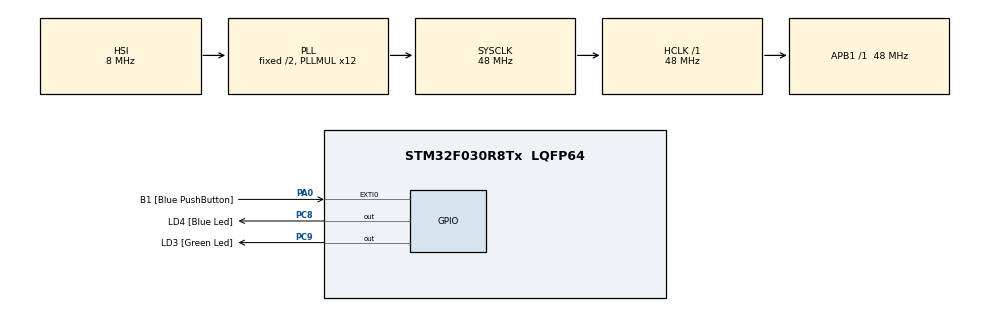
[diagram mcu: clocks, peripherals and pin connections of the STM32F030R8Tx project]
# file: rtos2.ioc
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Mcu.Family=STM32F0
FREERTOS.Tasks01=defaultTask,0,128,StartDefaultTask,Default,NULL,Dynamic,NULL,NULL
PC9.GPIO_Label=LD3 [Green Led]
PA14.GPIO_Label=SWCLK
PA0.GPIO_Label=B1 [Blue PushButton]
PC8.Signal=GPIO_Output
RCC.SYSCLKSource=RCC_SYSCLKSOURCE_PLLCLK
ProjectManager.StackSize=0x400
PC8.GPIO_Label=LD4 [Blue Led]
PA13.Signal=SYS_SWDIO
ProjectManager.TargetToolchain=STM32CubeIDE
RCC.HCLKFreq_Value=48000000
RCC.AHBFreq_Value=48000000
board=STM32F0308-DISCO
RCC.PLLMUL=RCC_PLL_MUL12
PA14.Mode=Serial_Wire
PA0.GPIO_ModeDefaultEXTI=GPIO_MODE_EVT_RISING
VP_SYS_VS_tim1.Mode=TIM1
VP_FREERTOS_VS_CMSIS_V1.Mode=CMSIS_V1
PA13.Mode=Serial_Wire
Mcu.Name=STM32F030R8Tx
PA13.GPIO_Label=SWDIO
PA0.Signal=GPXTI0
RCC.SYSCLKFreq_VALUE=48000000
Mcu.Package=LQFP64
NVIC.TimeBase=TIM1_BRK_UP_TRG_COM_IRQn
NVIC.TimeBaseIP=TIM1
PA14.Signal=SYS_SWCLK
ProjectManager.HeapSize=0x200
RCC.APB1TimFreq_Value=48000000
PC9.Signal=GPIO_Output
RCC.APB1Freq_Value=48000000
NVIC.TIM1_BRK_UP_TRG_COM_IRQn=true\:0\:0\:false\:false\:true\:false\:false\:true

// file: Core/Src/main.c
/* USER CODE BEGIN Header */
/**
  ******************************************************************************
  * @file           : main.c
  * @brief          : Main program body
  ******************************************************************************
  * @attention
  *
  * <h2><center>&copy; Copyright (c) 2021 STMicroelectronics.
  * All rights reserved.</center></h2>
  *
  * This software component is licensed by ST under BSD 3-Clause license,
  * the "License"; You may not use this file except in compliance with the
  * License. You may obtain a copy of the License at:
  *                        opensource.org/licenses/BSD-3-Clause
  *
  ******************************************************************************
  */
/* USER CODE END Header */
#include "main.h"
#include "cmsis_os.h"
#include "stdio.h"

osThreadId defaultTaskHandle;

void SystemClock_Config(void);
static void MX_GPIO_Init(void);
void StartDefaultTask(void const * argument);

/* USER CODE BEGIN PFP */
int count = 0;
/* USER CODE END PFP */

int main(void)
{

  /* MCU Configuration--------------------------------------------------------*/

  /* Reset of all peripherals, Initializes the Flash interface and the Systick. */
  HAL_Init();

  /* Configure the system clock */
  SystemClock_Config();

  /* Initialize all configured peripherals */
  MX_GPIO_Init();

  /* Create the thread(s) */
  /* definition and creation of defaultTask */
  osThreadDef(defaultTask, StartDefaultTask, osPriorityNormal, 0, 128);
  defaultTaskHandle = osThreadCreate(osThread(defaultTask), NULL);

  /* Start scheduler */
  osKernelStart();

  /* We should never get here as control is now taken by the scheduler */
  /* Infinite loop */
  while (1)
  {

  }
}

void SystemClock_Config(void)
{
  RCC_OscInitTypeDef RCC_OscInitStruct = {0};
  RCC_ClkInitTypeDef RCC_ClkInitStruct = {0};

  /** Initializes the RCC Oscillators according to the specified parameters
  * in the RCC_OscInitTypeDef structure.
  */
  RCC_OscInitStruct.OscillatorType = RCC_OSCILLATORTYPE_HSI;
  RCC_OscInitStruct.HSIState = RCC_HSI_ON;
  RCC_OscInitStruct.HSICalibrationValue = RCC_HSICALIBRATION_DEFAULT;
  RCC_OscInitStruct.PLL.PLLState = RCC_PLL_ON;
  RCC_OscInitStruct.PLL.PLLSource = RCC_PLLSOURCE_HSI;
  RCC_OscInitStruct.PLL.PLLMUL = RCC_PLL_MUL12;
  RCC_OscInitStruct.PLL.PREDIV = RCC_PREDIV_DIV1;
  if (HAL_RCC_OscConfig(&RCC_OscInitStruct) != HAL_OK)
  {
    Error_Handler();
  }
  /** Initializes the CPU, AHB and APB buses clocks
  */
  RCC_ClkInitStruct.ClockType = RCC_CLOCKTYPE_HCLK|RCC_CLOCKTYPE_SYSCLK
                              |RCC_CLOCKTYPE_PCLK1;
  RCC_ClkInitStruct.SYSCLKSource = RCC_SYSCLKSOURCE_PLLCLK;
  RCC_ClkInitStruct.AHBCLKDivider = RCC_SYSCLK_DIV1;
  RCC_ClkInitStruct.APB1CLKDivider = RCC_HCLK_DIV1;

  if (HAL_RCC_ClockConfig(&RCC_ClkInitStruct, FLASH_LATENCY_1) != HAL_OK)
  {
    Error_Handler();
  }
}

static void MX_GPIO_Init(void)
{
  GPIO_InitTypeDef GPIO_InitStruct = {0};

  /* GPIO Ports Clock Enable */
  __HAL_RCC_GPIOA_CLK_ENABLE();
  __HAL_RCC_GPIOC_CLK_ENABLE();

  /*Configure GPIO pin Output Level */
  HAL_GPIO_WritePin(GPIOC, LD4_Pin|LD3_Pin, GPIO_PIN_RESET);

  /*Configure GPIO pin : B1_Pin */
  GPIO_InitStruct.Pin = B1_Pin;
  GPIO_InitStruct.Mode = GPIO_MODE_EVT_RISING;
  GPIO_InitStruct.Pull = GPIO_NOPULL;
  HAL_GPIO_Init(B1_GPIO_Port, &GPIO_InitStruct);

  /*Configure GPIO pins : LD4_Pin LD3_Pin */
  GPIO_InitStruct.Pin = LD4_Pin|LD3_Pin;
  GPIO_InitStruct.Mode = GPIO_MODE_OUTPUT_PP;
  GPIO_InitStruct.Pull = GPIO_NOPULL;
  GPIO_InitStruct.Speed = GPIO_SPEED_FREQ_LOW;
  HAL_GPIO_Init(GPIOC, &GPIO_InitStruct);

}

void StartDefaultTask(void const * argument)
{
  /* USER CODE BEGIN 5 */
  /* Infinite loop */
  for(;;)
  {
	 // print = "hello";
	HAL_GPIO_TogglePin(GPIOC, LD3_Pin);
    osDelay(1000);
    count++;
    if(count == 10)
    {
    	osThreadTerminate (defaultTaskHandle);
    }
  }
  /* USER CODE END 5 */
}

 /**
  * @brief  Period elapsed callback in non blocking mode
  * @note   This function is called  when TIM1 interrupt took place, inside
  * HAL_TIM_IRQHandler(). It makes a direct call to HAL_IncTick() to increment
  * a global variable "uwTick" used as application time base.
  * @param  htim : TIM handle
  * @retval None
  */
void HAL_TIM_PeriodElapsedCallback(TIM_HandleTypeDef *htim)
{
  if (htim->Instance == TIM1) {
    HAL_IncTick();
  }
}

void Error_Handler(void)
{
  __disable_irq();
  while (1)
  {
  }
}

/************************ (C) COPYRIGHT STMicroelectronics *****END OF FILE****/
